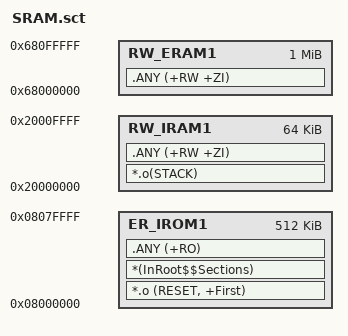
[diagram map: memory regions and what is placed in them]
; *************************************************************
; *** Scatter-Loading Description File generated by uVision ***
; *************************************************************
LR_IROM1 0x08000000 0x00080000{    ; load region size region
	ER_IROM1 0x08000000 0x00080000 {    ; load address = execution address
	*.o (RESET, +First)
	*(InRoot$$Sections)
	.ANY (+RO)
	}
	RW_IRAM1 0x20000000 0x00010000 {  ; RW data
	
	;默认情况下以下属性的内容都会被分配到RW_IRAM1，所以可注释掉
	*.o(STACK)       					;选择STACK节区，栈
	;stm32f10x_rcc.o(+RW)            	;选择stm32f10x_rcc的RW内容
	
	.ANY (+RW +ZI)
	}
	
	RW_ERAM1 0x68000000 0x100000 {  ; 外部SRMA
	;*.o(HEAP)                         ; 选择堆区
	.ANY (+RW +ZI)                      ; 其余的RW/ZI-data都分配到这里
	}
}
